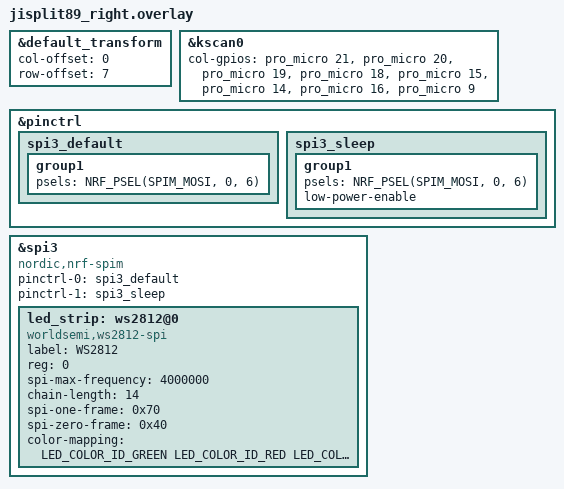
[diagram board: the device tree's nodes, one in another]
#include "jisplit89.dtsi"

&default_transform {
    col-offset = <0>;
    row-offset = <7>;
};

&kscan0 {
    col-gpios
        = <&pro_micro 21 GPIO_ACTIVE_HIGH> // F4 - col 0
        , <&pro_micro 20 GPIO_ACTIVE_HIGH> // F5 - col 1
        , <&pro_micro 19 GPIO_ACTIVE_HIGH> // F6 - col 2
        , <&pro_micro 18 GPIO_ACTIVE_HIGH> // F7 - col 3
        , <&pro_micro 15 GPIO_ACTIVE_HIGH> // B1 - col 4
        , <&pro_micro 14 GPIO_ACTIVE_HIGH> // B3 - col 5
        , <&pro_micro 16 GPIO_ACTIVE_HIGH> // B2 - col 6
        , <&pro_micro 9 GPIO_ACTIVE_HIGH>  // B5 - col 7
        ;
};

&pinctrl {
    spi3_default: spi3_default {
        group1 {
            psels = <NRF_PSEL(SPIM_MOSI, 0, 6)>;
        };
    };

    spi3_sleep: spi3_sleep {
        group1 {
            psels = <NRF_PSEL(SPIM_MOSI, 0, 6)>;
            low-power-enable;
        };
    };
};

&spi3 {
    compatible = "nordic,nrf-spim";
    status = "okay";

    pinctrl-0 = <&spi3_default>;
    pinctrl-1 = <&spi3_sleep>;
    pinctrl-names = "default", "sleep";

    led_strip: ws2812@0 {
        compatible = "worldsemi,ws2812-spi";
        label = "WS2812";

        /* SPI */
        reg = <0>; /* ignored, but necessary for SPI bindings */
        spi-max-frequency = <4000000>;

        /* WS2812 */
        chain-length = <14>; /* 14 LEDs on right side */
        spi-one-frame = <0x70>;
        spi-zero-frame = <0x40>;

        color-mapping = <LED_COLOR_ID_GREEN LED_COLOR_ID_RED LED_COLOR_ID_BLUE>;
    };
};
